AUTOSAR XML (schema 4-2-2)
package /Components
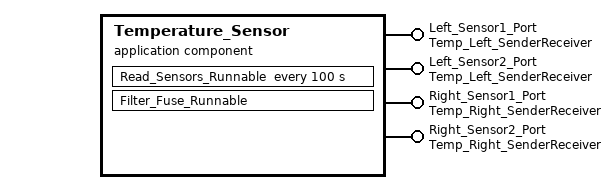
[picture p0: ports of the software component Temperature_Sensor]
  application sw component type Temperature_Sensor
    4 x provide port:
      Left_Sensor1_Port: provided-interface=Temp_Left_SenderReceiver
      Left_Sensor2_Port: provided-interface=Temp_Left_SenderReceiver
      Right_Sensor1_Port: provided-interface=Temp_Right_SenderReceiver
      Right_Sensor2_Port: provided-interface=Temp_Right_SenderReceiver
    behavior Temperature_Sensor_Behavior
      data write completed event Publish_Completed_Event_Left: start-on-event=Filter_Fuse_Runnable, event-source=Publish_Left_Seat_Temperature
      data write completed event Publish_Completed_Event_Right: start-on-event=Filter_Fuse_Runnable, event-source=Publish_Right_Seat_Temperature
      init event Init_Calibration_Event: start-on-event=Read_Sensors_Runnable
      timing event Periodic_Sample_Event: start-on-event=Read_Sensors_Runnable, period=100
      runnable Read_Sensors_Runnable: minimum-start-interval=100, symbol=R_ReadSensors
        data-read-access:
          4 x access:
            Read_Left_Sensor1: accessed-variable={autosar-variable=Left_Sensor1_Port.Left_Sensor1_Raw, local-variable=LeftSensor1_ADC}
            Read_Left_Sensor2: accessed-variable={autosar-variable=Left_Sensor2_Port.Left_Sensor2_Raw, local-variable=LeftSensor2_ADC}
            Read_Right_Sensor1: accessed-variable={autosar-variable=Right_Sensor1_Port.Right_Sensor1_Raw, local-variable=RightSensor1_ADC}
            Read_Right_Sensor2: accessed-variable={autosar-variable=Right_Sensor2_Port.Right_Sensor2_Raw, local-variable=RightSensor2_ADC}
        data-send-points:
          4 x access:
            Store_Left_Sensor1_Buffer: accessed-variable={autosar-variable=Left_Sensor1_Port.Left_Sensor1_Buffer, local-variable=LeftSensor1_Buffer}
            Store_Left_Sensor2_Buffer: accessed-variable={autosar-variable=Left_Sensor2_Port.Left_Sensor2_Buffer, local-variable=LeftSensor2_Buffer}
            Store_Right_Sensor1_Buffer: accessed-variable={autosar-variable=Right_Sensor1_Port.Right_Sensor1_Buffer, local-variable=RightSensor1_Buffer}
            Store_Right_Sensor2_Buffer: accessed-variable={autosar-variable=Right_Sensor2_Port.Right_Sensor2_Buffer, local-variable=RightSensor2_Buffer}
        internal triggering point Sampling_Timer
      runnable Filter_Fuse_Runnable: minimum-start-interval=100, symbol=R_FilterFuse
        data-read-access:
          access Read_Left_Buffers: accessed-variable={autosar-variable=Left_Sensor1_Port.Left_Sensor_Fuse_Input, local-variable=LeftSensor1_Buffer}
          access Read_Right_Buffers: accessed-variable={autosar-variable=Right_Sensor1_Port.Right_Sensor_Fuse_Input, local-variable=RightSensor1_Buffer}
        data-send-points:
          access Publish_Left_Seat_Temperature: accessed-variable={autosar-variable=Left_Sensor1_Port.Left_Seat_Fused_Temperature, local-variable=Left_Seat_Fused}
          access Publish_Right_Seat_Temperature: accessed-variable={autosar-variable=Right_Sensor1_Port.Right_Seat_Fused_Temperature, local-variable=Right_Seat_Fused}
        internal triggering point Filter_Trigger
